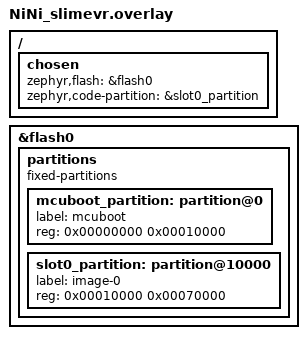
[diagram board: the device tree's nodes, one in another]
&flash0 {
  partitions {
    compatible = "fixed-partitions";
    #address-cells = <1>;
    #size-cells = <1>;

    mcuboot_partition: partition@0 {
      label = "mcuboot";
      reg = <0x00000000 0x00010000>;
    };

    slot0_partition: partition@10000 {
      label = "image-0";
      reg = <0x00010000 0x00070000>;
    };
  };
};

/ {
  chosen {
    zephyr,flash = &flash0;
    zephyr,code-partition = &slot0_partition;
  };
};
